# STM32L471QEI3 register map
File version: 1.0
Registers are 32-bit, access not given, reset 0x0 unless marked. A register's access mark holds for its fields unless they carry their own. Offsets are from the block's base; [hi:lo] are bit positions; {n}, {i} and the like mark numbered series.

## SYSCFG
Base 0x40010000
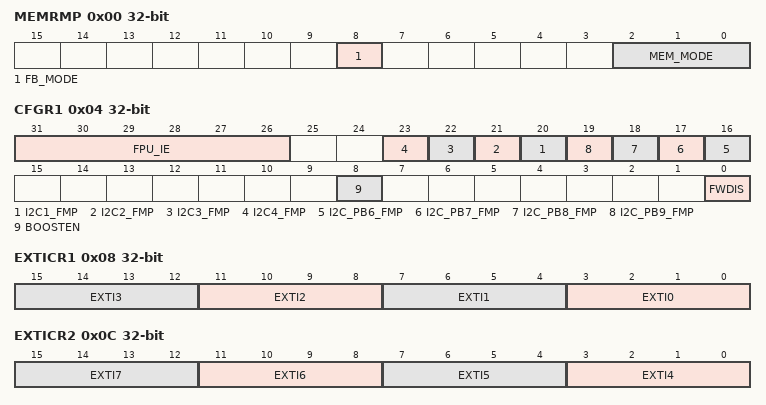
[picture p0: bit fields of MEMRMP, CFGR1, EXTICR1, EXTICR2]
0x00 MEMRMP
  [8] FB_MODE, [2:0] MEM_MODE
0x04 CFGR1
  [31:26] FPU_IE, [n+19] I2C{n}_FMP (n=1..4), [n+10] I2C_PB{n}_FMP (n=6..9), [8] BOOSTEN, [0] FWDIS
0x08 EXTICR1
  [4n+3:4n] EXTI{n} (n=0..3)
0x0C EXTICR2
  [4n-13:4n-16] EXTI{n} (n=4..7)
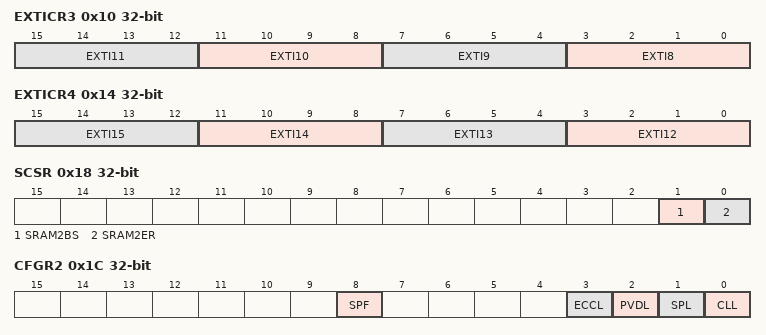
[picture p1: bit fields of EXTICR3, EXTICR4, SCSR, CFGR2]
0x10 EXTICR3
  [4n-29:4n-32] EXTI{n} (n=8..11)
0x14 EXTICR4
  [4n-45:4n-48] EXTI{n} (n=12..15)
0x18 SCSR
  [1] SRAM2BS, [0] SRAM2ER
0x1C CFGR2
  [8] SPF, [3] ECCL, [2] PVDL, [1] SPL, [0] CLL
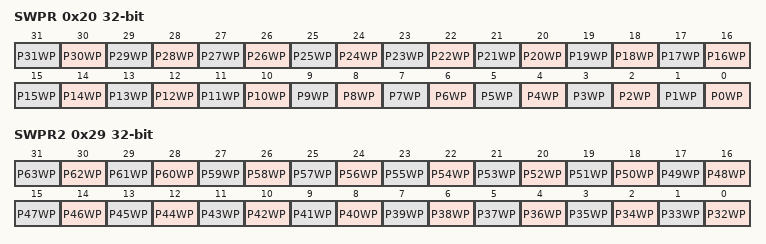
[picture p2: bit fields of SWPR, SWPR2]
0x20 SWPR
  [n] P{n}WP (n=0..31)
0x24 SKR
  [7:0] KEY
0x29 SWPR2
  [n-32] P{n}WP (n=32..63)

## VREFBUF
Base 0x40010030
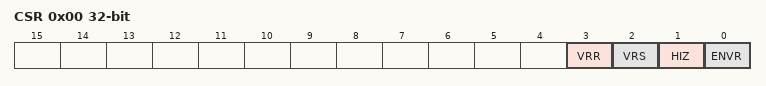
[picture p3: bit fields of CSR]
0x00 CSR
  [3] VRR, [2] VRS, [1] HIZ, [0] ENVR
0x04 CCR
  [5:0] TRIM

## COMP
Base 0x40010200
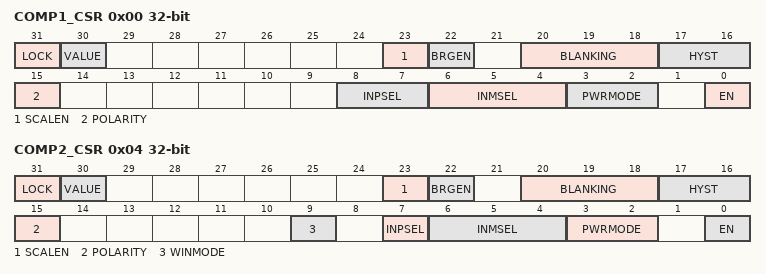
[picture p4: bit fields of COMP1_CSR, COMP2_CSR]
0x00 COMP1_CSR
  [31] LOCK, [30] VALUE, [23] SCALEN, [22] BRGEN, [20:18] BLANKING, [17:16] HYST, [15] POLARITY, [8:7] INPSEL, [6:4] INMSEL, [3:2] PWRMODE, [0] EN
0x04 COMP2_CSR
  [31] LOCK, [30] VALUE, [23] SCALEN, [22] BRGEN, [20:18] BLANKING, [17:16] HYST, [15] POLARITY, [9] WINMODE, [7] INPSEL, [6:4] INMSEL, [3:2] PWRMODE, [0] EN

## EXTI
Base 0x40010400
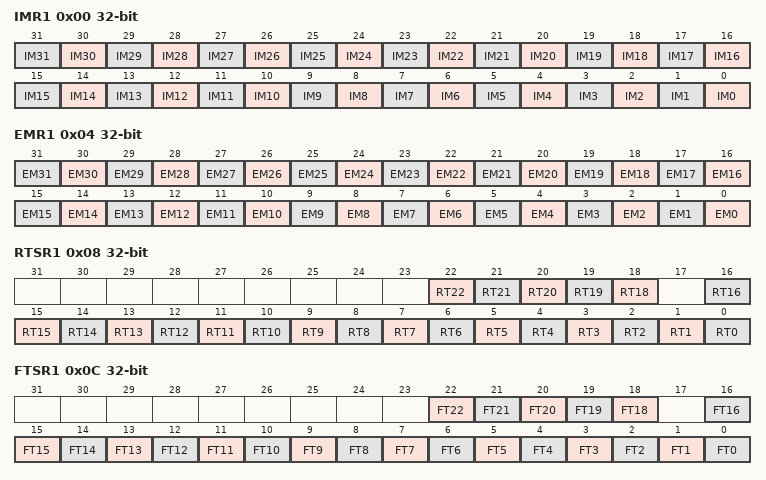
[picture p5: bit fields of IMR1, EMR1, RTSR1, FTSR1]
0x00 IMR1
  [n] IM{n} (n=0..31)
0x04 EMR1
  [n] EM{n} (n=0..31)
0x08 RTSR1
  [n] RT{n} (n=18..22), [n] RT{n} (n=0..16)
0x0C FTSR1
  [n] FT{n} (n=18..22), [n] FT{n} (n=0..16)
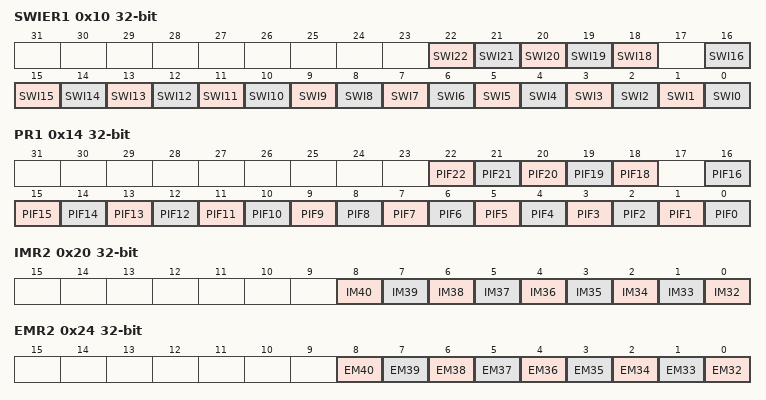
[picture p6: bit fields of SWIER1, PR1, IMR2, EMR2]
0x10 SWIER1
  [n] SWI{n} (n=18..22), [n] SWI{n} (n=0..16)
0x14 PR1
  [n] PIF{n} (n=18..22), [n] PIF{n} (n=0..16)
0x20 IMR2
  [n-32] IM{n} (n=32..40)
0x24 EMR2
  [n-32] EM{n} (n=32..40)
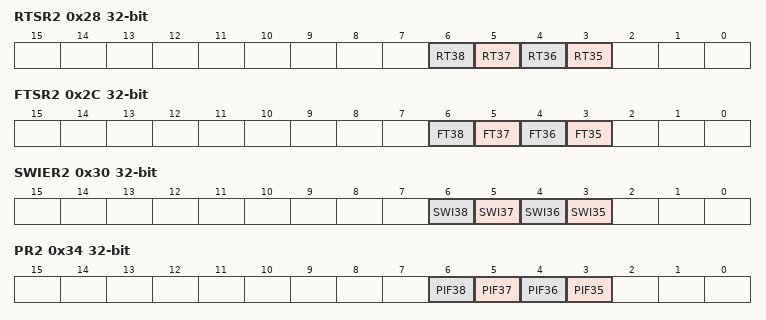
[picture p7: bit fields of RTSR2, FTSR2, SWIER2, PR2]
0x28 RTSR2
  [n-32] RT{n} (n=35..38)
0x2C FTSR2
  [n-32] FT{n} (n=35..38)
0x30 SWIER2
  [n-32] SWI{n} (n=35..38)
0x34 PR2
  [n-32] PIF{n} (n=35..38)

## FW
Base 0x40011C00
0x00 CSSA
  [23:8] ADD
0x04 CSL
  [21:8] LENG
0x08 NVDSSA
  [23:8] ADD
0x0C NVDSL
  [21:8] LENG
0x10 VDSSA
  [17:6] ADD
0x14 VDSL
  [17:6] LENG
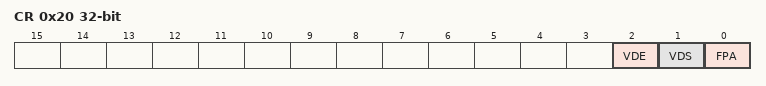
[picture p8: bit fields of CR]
0x20 CR
  [2] VDE, [1] VDS, [0] FPA

## SDMMC1
Base 0x40012800
0x00 POWER
  [1:0] PWRCTRL
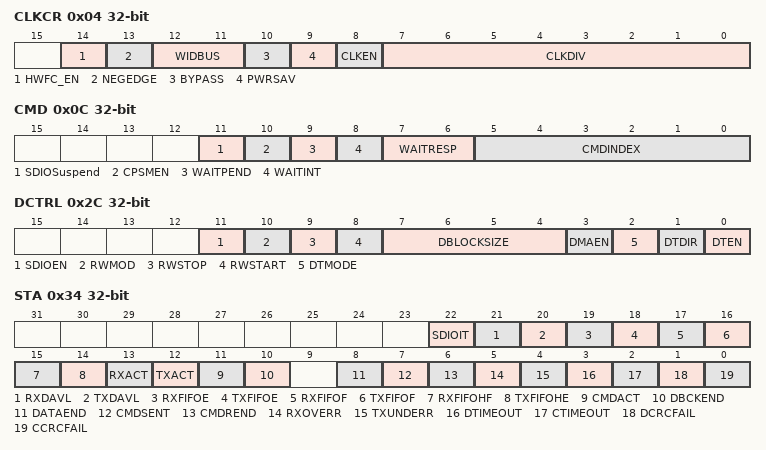
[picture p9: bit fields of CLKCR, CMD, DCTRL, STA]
0x04 CLKCR
  [14] HWFC_EN, [13] NEGEDGE, [12:11] WIDBUS, [10] BYPASS, [9] PWRSAV, [8] CLKEN, [7:0] CLKDIV
0x08 ARG
  [31:0] CMDARG
0x0C CMD
  [11] SDIOSuspend, [10] CPSMEN, [9] WAITPEND, [8] WAITINT, [7:6] WAITRESP, [5:0] CMDINDEX
0x10 RESPCMD
  [5:0] RESPCMD
{0x10+4i} RESP{i} (i=1..4)
  [31:0] CARDSTATUS{i}
0x24 DTIMER
  [31:0] DATATIME
0x28 DLEN
  [24:0] DATALENGTH
0x2C DCTRL
  [11] SDIOEN, [10] RWMOD, [9] RWSTOP, [8] RWSTART, [7:4] DBLOCKSIZE, [3] DMAEN, [2] DTMODE, [1] DTDIR, [0] DTEN
0x30 DCOUNT
  [24:0] DATACOUNT
0x34 STA
  [22] SDIOIT, [21] RXDAVL, [20] TXDAVL, [19] RXFIFOE, [18] TXFIFOE, [17] RXFIFOF, [16] TXFIFOF, [15] RXFIFOHF, [14] TXFIFOHE, [13] RXACT, [12] TXACT, [11] CMDACT, [10] DBCKEND, [8] DATAEND, [7] CMDSENT, [6] CMDREND, [5] RXOVERR, [4] TXUNDERR, [3] DTIMEOUT, [2] CTIMEOUT, [1] DCRCFAIL, [0] CCRCFAIL
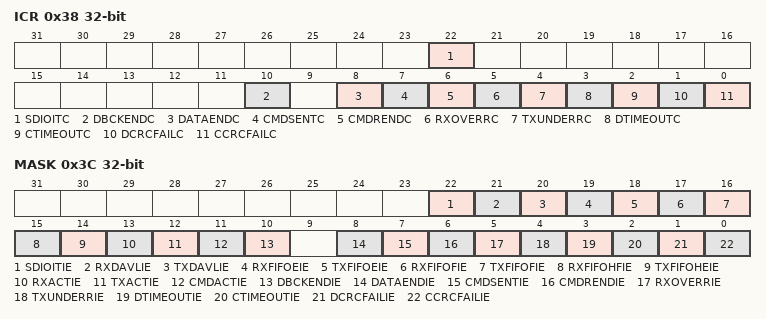
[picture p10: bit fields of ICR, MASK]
0x38 ICR
  [22] SDIOITC, [10] DBCKENDC, [8] DATAENDC, [7] CMDSENTC, [6] CMDRENDC, [5] RXOVERRC, [4] TXUNDERRC, [3] DTIMEOUTC, [2] CTIMEOUTC, [1] DCRCFAILC, [0] CCRCFAILC
0x3C MASK
  [22] SDIOITIE, [21] RXDAVLIE, [20] TXDAVLIE, [19] RXFIFOEIE, [18] TXFIFOEIE, [17] RXFIFOFIE, [16] TXFIFOFIE, [15] RXFIFOHFIE, [14] TXFIFOHEIE, [13] RXACTIE, [12] TXACTIE, [11] CMDACTIE, [10] DBCKENDIE, [8] DATAENDIE, [7] CMDSENTIE, [6] CMDRENDIE, [5] RXOVERRIE, [4] TXUNDERRIE, [3] DTIMEOUTIE, [2] CTIMEOUTIE, [1] DCRCFAILIE, [0] CCRCFAILIE
0x48 FIFOCNT
  [23:0] FIFOCOUNT
0x80 FIFO
  [31:0] FIF0Data

## TIM1
Base 0x40012C00
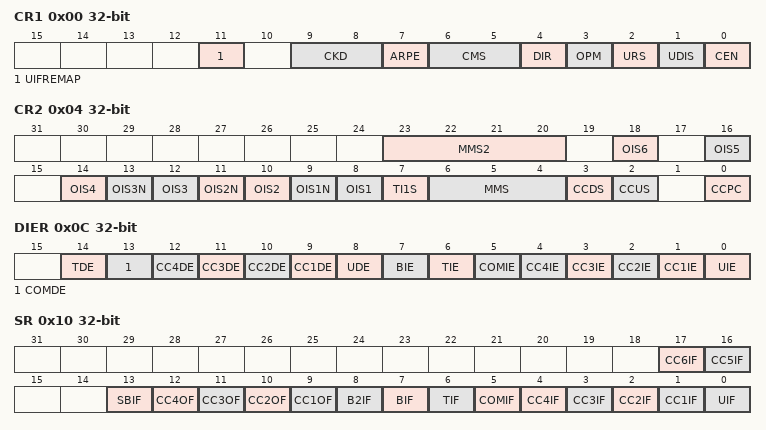
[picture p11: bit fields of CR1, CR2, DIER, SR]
0x00 CR1
  [11] UIFREMAP, [9:8] CKD, [7] ARPE, [6:5] CMS, [4] DIR, [3] OPM, [2] URS, [1] UDIS, [0] CEN
0x04 CR2
  [23:20] MMS2, [2n+6] OIS{n} (n=1..6), [13] OIS3N, [11] OIS2N, [9] OIS1N, [7] TI1S, [6:4] MMS, [3] CCDS, [2] CCUS, [0] CCPC
0x08 SMCR
  [15] ETP, [14] ECE, [13:12] ETPS, [11:8] ETF, [7] MSM, [6:4] TS, [3] OCCS, [16:0] SMS
0x0C DIER
  [14] TDE, [13] COMDE, [n+8] CC{n}DE (n=1..4), [8] UDE, [7] BIE, [6] TIE, [5] COMIE, [n] CC{n}IE (n=1..4), [0] UIE
0x10 SR
  [17] CC6IF, [16] CC5IF, [13] SBIF, [n+8] CC{n}OF (n=1..4), [8] B2IF, [7] BIF, [6] TIF, [5] COMIF, [n] CC{n}IF (n=1..4), [0] UIF
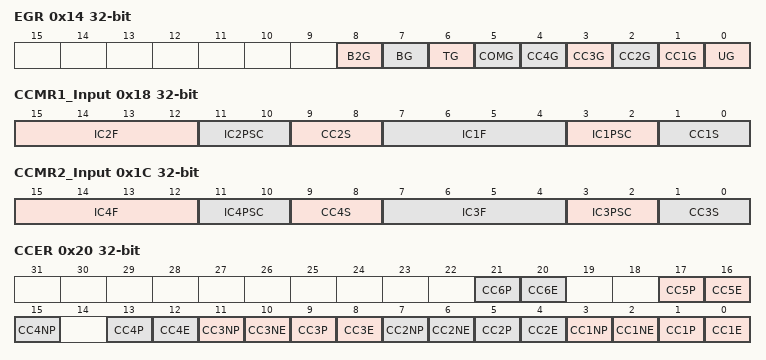
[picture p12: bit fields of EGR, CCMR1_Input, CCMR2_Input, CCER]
0x14 EGR
  [8] B2G, [7] BG, [6] TG, [5] COMG, [n] CC{n}G (n=1..4), [0] UG
0x18 CCMR1_Output
  [15] OC2CE, [24:12] OC2M, [11] OC2PE, [10] OC2FE, [9:8] CC2S, [7] OC1CE, [16:4] OC1M, [3] OC1PE, [2] OC1FE, [1:0] CC1S
0x18 CCMR1_Input
  [15:12] IC2F, [11:10] IC2PSC, [9:8] CC2S, [7:4] IC1F, [3:2] IC1PSC, [1:0] CC1S
0x1C CCMR2_Output
  [15] OC4CE, [24:12] OC4M, [11] OC4PE, [10] OC4FE, [9:8] CC4S, [7] OC3CE, [16:4] OC3M, [3] OC3PE, [2] OC3FE, [1:0] CC3S
0x1C CCMR2_Input
  [15:12] IC4F, [11:10] IC4PSC, [9:8] CC4S, [7:4] IC3F, [3:2] IC3PSC, [1:0] CC3S
0x20 CCER
  [4n-3] CC{n}P (n=1..6), [4n-4] CC{n}E (n=1..6), [4n-1] CC{n}NP (n=1..4), [10] CC3NE, [6] CC2NE, [2] CC1NE
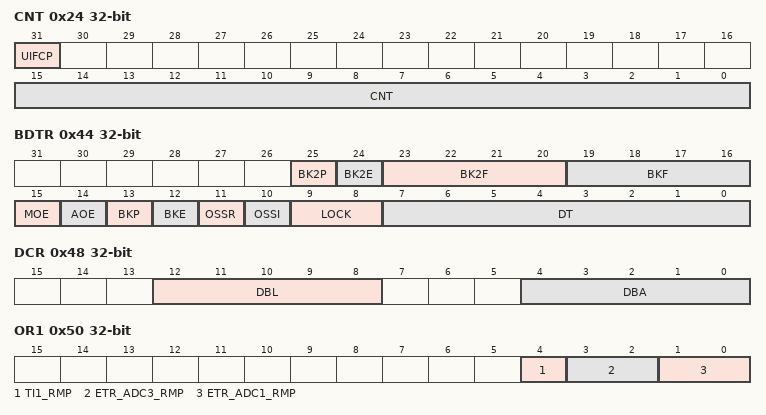
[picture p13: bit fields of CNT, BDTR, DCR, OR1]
0x24 CNT
  [31] UIFCP, [15:0] CNT
0x28 PSC
  [15:0] PSC
0x2C ARR
  [15:0] ARR
0x30 RCR
  [15:0] REP
{0x30+4i} CCR{i} (i=1..4)
  [15:0] CCR{i}
0x44 BDTR
  [25] BK2P, [24] BK2E, [23:20] BK2F, [19:16] BKF, [15] MOE, [14] AOE, [13] BKP, [12] BKE, [11] OSSR, [10] OSSI, [9:8] LOCK, [7:0] DT
0x48 DCR
  [12:8] DBL, [4:0] DBA
0x4C DMAR
  [31:0] DMAB
0x50 OR1
  [4] TI1_RMP, [3:2] ETR_ADC3_RMP, [1:0] ETR_ADC1_RMP
0x54 CCMR3_Output
  [15] OC6CE, [24:12] OC6M, [11] OC6PE, [10] OC6FE, [7] OC5CE, [16:4] OC5M, [3] OC5PE, [2] OC5FE
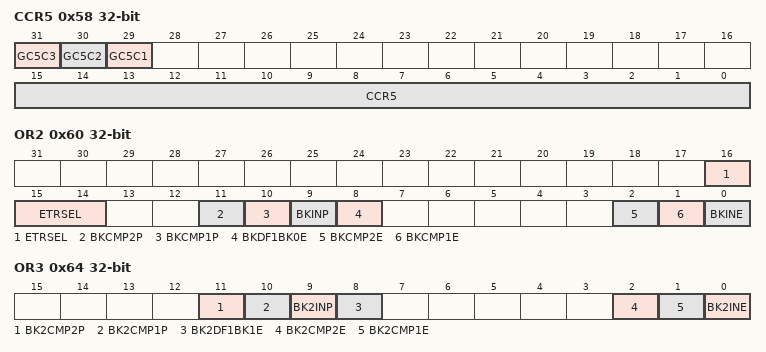
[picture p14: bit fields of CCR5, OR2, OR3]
0x58 CCR5
  [31] GC5C3, [30] GC5C2, [29] GC5C1, [15:0] CCR5
0x5C CCR6
  [15:0] CCR6
0x60 OR2
  [16:14] ETRSEL, [11] BKCMP2P, [10] BKCMP1P, [9] BKINP, [8] BKDF1BK0E, [2] BKCMP2E, [1] BKCMP1E, [0] BKINE
0x64 OR3
  [11] BK2CMP2P, [10] BK2CMP1P, [9] BK2INP, [8] BK2DF1BK1E, [2] BK2CMP2E, [1] BK2CMP1E, [0] BK2INE

## TIM8
Base 0x40013400
Registers as TIM1; these are added or differ:
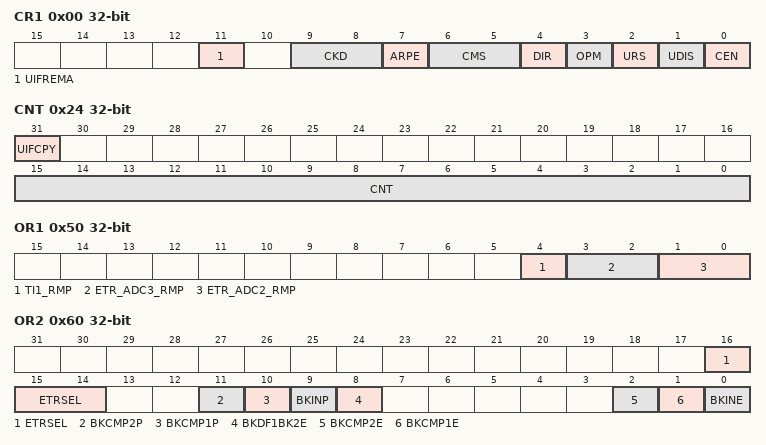
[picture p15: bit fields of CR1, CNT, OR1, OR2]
0x00 CR1
  [11] UIFREMA, [9:8] CKD, [7] ARPE, [6:5] CMS, [4] DIR, [3] OPM, [2] URS, [1] UDIS, [0] CEN
0x08 SMCR
  [15] ETP, [14] ECE, [13:12] ETPS, [11:8] ETF, [7] MSM, [6:4] TS, [16:0] SMS
0x24 CNT
  [31] UIFCPY, [15:0] CNT
0x50 OR1
  [4] TI1_RMP, [3:2] ETR_ADC3_RMP, [1:0] ETR_ADC2_RMP
0x60 OR2
  [16:14] ETRSEL, [11] BKCMP2P, [10] BKCMP1P, [9] BKINP, [8] BKDF1BK2E, [2] BKCMP2E, [1] BKCMP1E, [0] BKINE
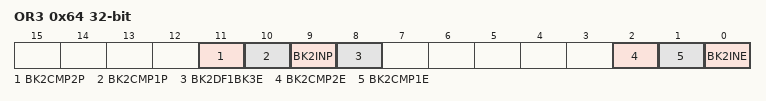
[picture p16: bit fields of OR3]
0x64 OR3
  [11] BK2CMP2P, [10] BK2CMP1P, [9] BK2INP, [8] BK2DF1BK3E, [2] BK2CMP2E, [1] BK2CMP1E, [0] BK2INE
